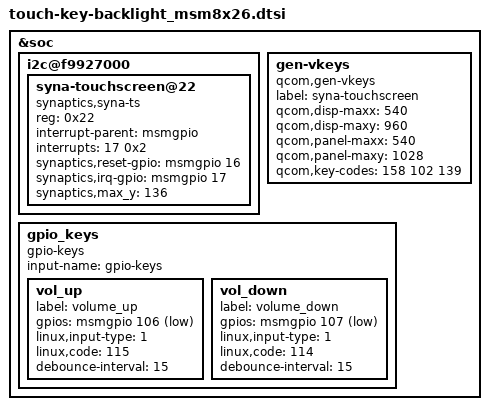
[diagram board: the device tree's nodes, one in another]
//for touchscreen and key and keypad-backlight

&soc {

i2c@f9927000 {
		syna-touchscreen@22 {
			compatible = "synaptics,syna-ts";
			reg = <0x22>;
			interrupt-parent = <&msmgpio>;
			interrupts = <17 0x2>;
			synaptics,reset-gpio = <&msmgpio 16 0x00>;
			synaptics,irq-gpio = <&msmgpio 17 0x00>;
			synaptics,max_y = <136>;
//			vdd-supply = <&pm8226_l19>;
//			vcc_i2c-supply = <&pm8226_lvs1>;
		};
	};

	gen-vkeys {
		compatible = "qcom,gen-vkeys";
		label = "syna-touchscreen";
		qcom,disp-maxx = <540>;
		qcom,disp-maxy = <960>;
		qcom,panel-maxx = <540>;
		qcom,panel-maxy = <1028>;
		qcom,key-codes = <158 102 139>;
	};
	
	gpio_keys {
			compatible = "gpio-keys";
			input-name = "gpio-keys";
	
			vol_up {
				label = "volume_up";
				gpios = <&msmgpio 106 0x1>;
				linux,input-type = <1>;
				linux,code = <115>;
				debounce-interval = <15>;
			};
			/*ergate*/
			vol_down {
				label = "volume_down";
				gpios = <&msmgpio 107 0x1>;
				linux,input-type = <1>;
				linux,code = <114>;
				debounce-interval = <15>;
			};
		};

};
